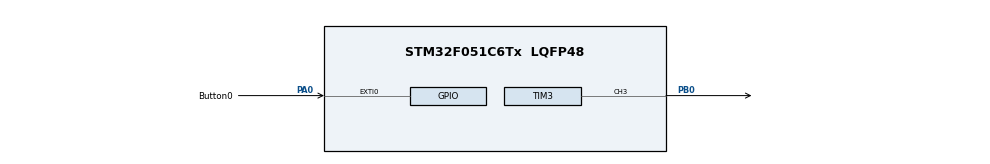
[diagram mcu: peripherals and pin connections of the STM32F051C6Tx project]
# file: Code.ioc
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Dma.Request0=TIM2_CH1
Dma.TIM2_CH1.0.Direction=DMA_MEMORY_TO_PERIPH
Dma.TIM2_CH1.0.Instance=DMA1_Channel5
Dma.TIM2_CH1.0.MemDataAlignment=DMA_MDATAALIGN_WORD
Dma.TIM2_CH1.0.MemInc=DMA_MINC_ENABLE
Dma.TIM2_CH1.0.Mode=DMA_CIRCULAR
Dma.TIM2_CH1.0.PeriphDataAlignment=DMA_PDATAALIGN_WORD
Dma.TIM2_CH1.0.PeriphInc=DMA_PINC_DISABLE
Dma.TIM2_CH1.0.Priority=DMA_PRIORITY_LOW
Mcu.Family=STM32F0
Mcu.Name=STM32F051C6Tx
Mcu.Package=LQFP48
NVIC.DMA1_Channel4_5_IRQn=true\:0\:0\:false\:true\:true\:1\:false\:true\:true
NVIC.EXTI0_1_IRQn=true\:1\:0\:true\:true\:true\:2\:true\:true\:true
PA0.GPIO_Label=Button0
PA0.GPIO_PuPd=GPIO_PULLUP
PA0.Signal=GPXTI0
PA13.Mode=Serial_Wire
PA13.Signal=SYS_SWDIO
PA14.Mode=Serial_Wire
PA14.Signal=SYS_SWCLK
PB0.Signal=S_TIM3_CH3
PF0-OSC_IN.Mode=HSE-External-Oscillator
PF0-OSC_IN.Signal=RCC_OSC_IN
PF1-OSC_OUT.Mode=HSE-External-Oscillator
PF1-OSC_OUT.Signal=RCC_OSC_OUT
ProjectManager.HeapSize=0x200
ProjectManager.StackSize=0x400
ProjectManager.TargetToolchain=STM32CubeIDE
SH.S_TIM3_CH3.0=TIM3_CH3,PWM Generation3 CH3
TIM2.Channel-Output\ Compare1\ No\ Output=TIM_CHANNEL_1
TIM2.Period=100
TIM3.Channel-PWM\ Generation3\ CH3=TIM_CHANNEL_3
TIM3.Period=1023
VP_TIM2_VS_no_output1.Mode=Output Compare1 No Output
board=custom

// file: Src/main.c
/* USER CODE BEGIN Header */
/**
  ******************************************************************************
  * @file           : main.c
  * @brief          : Main program body
  ******************************************************************************
  * @attention
  *
  * Copyright (c) 2023 STMicroelectronics.
  * All rights reserved.
  *
  * This software is licensed under terms that can be found in the LICENSE file
  * in the root directory of this software component.
  * If no LICENSE file comes with this software, it is provided AS-IS.
  *
  ******************************************************************************
  */
/* USER CODE END Header */
#include "main.h"
#include "dma.h"
#include "tim.h"
#include "gpio.h"

/* USER CODE BEGIN Includes */
#include <stdio.h>
#include "stm32f0xx.h"
#include <lcd_stm32f0.c>
/* USER CODE END Includes */

/* USER CODE BEGIN PTD */
#define NS        // Number of samples in LUT
#define TIM2CLK   // STM Clock frequency
#define F_SIGNAL  // Frequency of output analog signal
/* USER CODE END PTD */

/* USER CODE BEGIN PV */
// TODO: Add code for global variables, including LUTs

uint32_t Sin_LUT[NS] = {};

uint32_t saw_LUT[NS] = {};

uint32_t triangle_LUT[NS] = {};

// TODO: Equation to calculate TIM2_Ticks
uint32_t TIM2_Ticks = 0; // How often to write new LUT value
uint32_t DestAddress = (uint32_t) &(TIM3->CCR3); // Write LUT TO TIM3->CCR3 to modify PWM duty cycle

/* USER CODE END PV */

void SystemClock_Config(void);

static void MX_NVIC_Init(void);

/* USER CODE BEGIN PFP */
void EXTI0_1_IRQHandler(void);
/* USER CODE END PFP */

int main(void) {

    /* MCU Configuration--------------------------------------------------------*/

    /* Reset of all peripherals, Initializes the Flash interface and the Systick. */
    HAL_Init();

    /* USER CODE BEGIN Init */
    init_LCD();
    /* USER CODE END Init */

    /* Configure the system clock */
    SystemClock_Config();

    /* Initialize all configured peripherals */
    MX_GPIO_Init();
    MX_DMA_Init();
    MX_TIM2_Init();
    MX_TIM3_Init();

    /* Initialize interrupts */
    MX_NVIC_Init();
    /* USER CODE BEGIN 2 */
    // TODO: Start TIM3 in PWM mode on channel 3

    // TODO: Start TIM2 in Output Compare (OC) mode on channel 1.

    // TODO: Start DMA in IT mode on TIM2->CH1; Source is LUT and Dest is TIM3->CCR3; start with Sine LUT

    // TODO: Write current waveform to LCD ("Sine")
    delay(3000);

    // TODO: Enable DMA (start transfer from LUT to CCR)

    /* USER CODE END 2 */

    /* Infinite loop */
    while (1) {

    }
}

void SystemClock_Config(void) {
    RCC_OscInitTypeDef RCC_OscInitStruct = {0};
    RCC_ClkInitTypeDef RCC_ClkInitStruct = {0};

    /** Initializes the RCC Oscillators according to the specified parameters
    * in the RCC_OscInitTypeDef structure.
    */
    RCC_OscInitStruct.OscillatorType = RCC_OSCILLATORTYPE_HSI;
    RCC_OscInitStruct.HSIState = RCC_HSI_ON;
    RCC_OscInitStruct.HSICalibrationValue = RCC_HSICALIBRATION_DEFAULT;
    RCC_OscInitStruct.PLL.PLLState = RCC_PLL_NONE;
    if (HAL_RCC_OscConfig(&RCC_OscInitStruct) != HAL_OK) {
        Error_Handler();
    }

    /** Initializes the CPU, AHB and APB buses clocks
    */
    RCC_ClkInitStruct.ClockType = RCC_CLOCKTYPE_HCLK | RCC_CLOCKTYPE_SYSCLK
                                  | RCC_CLOCKTYPE_PCLK1;
    RCC_ClkInitStruct.SYSCLKSource = RCC_SYSCLKSOURCE_HSI;
    RCC_ClkInitStruct.AHBCLKDivider = RCC_SYSCLK_DIV1;
    RCC_ClkInitStruct.APB1CLKDivider = RCC_HCLK_DIV1;

    if (HAL_RCC_ClockConfig(&RCC_ClkInitStruct, FLASH_LATENCY_0) != HAL_OK) {
        Error_Handler();
    }
}

/**
  * @brief NVIC Configuration.
  * @retval None
  */
static void MX_NVIC_Init(void) {
    /* DMA1_Channel4_5_IRQn interrupt configuration */
    HAL_NVIC_SetPriority(DMA1_Channel4_5_IRQn, 0, 0);
    HAL_NVIC_EnableIRQ(DMA1_Channel4_5_IRQn);
    /* EXTI0_1_IRQn interrupt configuration */
    HAL_NVIC_SetPriority(EXTI0_1_IRQn, 0, 0);
    HAL_NVIC_EnableIRQ(EXTI0_1_IRQn);
}

/* USER CODE BEGIN 4 */
void HAL_GPIO_EXTI_Callback(uint16_t GPIO_Pin) {
    if (GPIO_Pin == Button0_Pin) {

    }
}
/* USER CODE END 4 */

void Error_Handler(void) {
    __disable_irq();
    while (1) {
    }
}
